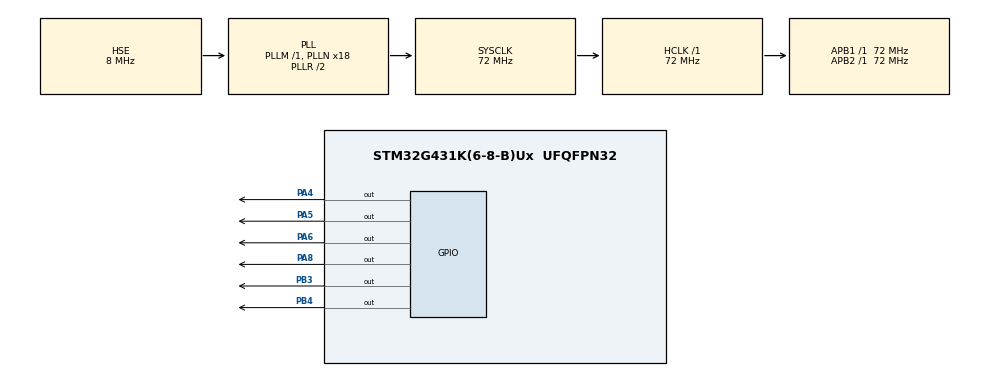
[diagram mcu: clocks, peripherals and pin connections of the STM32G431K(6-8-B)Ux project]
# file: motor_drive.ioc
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Mcu.Family=STM32G4
Mcu.Name=STM32G431K(6-8-B)Ux
Mcu.Package=UFQFPN32
NVIC.PriorityGroup=NVIC_PRIORITYGROUP_4
PA13.Mode=Serial_Wire
PA13.Signal=SYS_JTMS-SWDIO
PA14.Mode=Serial_Wire
PA14.Signal=SYS_JTCK-SWCLK
PA4.GPIO_PuPd=GPIO_PULLUP
PA4.PinState=GPIO_PIN_RESET
PA4.Signal=GPIO_Output
PA5.GPIO_PuPd=GPIO_PULLUP
PA5.PinState=GPIO_PIN_RESET
PA5.Signal=GPIO_Output
PA6.GPIO_PuPd=GPIO_PULLUP
PA6.PinState=GPIO_PIN_SET
PA6.Signal=GPIO_Output
PA8.GPIO_PuPd=GPIO_PULLUP
PA8.PinState=GPIO_PIN_SET
PA8.Signal=GPIO_Output
PB3.GPIO_PuPd=GPIO_PULLUP
PB3.GPIO_Speed=GPIO_SPEED_FREQ_VERY_HIGH
PB3.Signal=GPIO_Output
PB4.GPIO_PuPd=GPIO_PULLUP
PB4.GPIO_Speed=GPIO_SPEED_FREQ_VERY_HIGH
PB4.PinState=GPIO_PIN_SET
PB4.Signal=GPIO_Output
PF0-OSC_IN.Mode=HSE-External-Oscillator
PF0-OSC_IN.Signal=RCC_OSC_IN
PF1-OSC_OUT.Mode=HSE-External-Oscillator
PF1-OSC_OUT.Signal=RCC_OSC_OUT
ProjectManager.HeapSize=0x200
ProjectManager.StackSize=0x400
ProjectManager.TargetToolchain=MDK-ARM V5.32
RCC.ADC12Freq_Value=72000000
RCC.AHBFreq_Value=72000000
RCC.APB1Freq_Value=72000000
RCC.APB1TimFreq_Value=72000000
RCC.APB2Freq_Value=72000000
RCC.APB2TimFreq_Value=72000000
RCC.CortexFreq_Value=72000000
RCC.EXTERNAL_CLOCK_VALUE=12288000
RCC.HCLKFreq_Value=72000000
RCC.HSE_VALUE=8000000
RCC.HSI48_VALUE=48000000
RCC.HSI_VALUE=16000000
RCC.LSE_VALUE=32768
RCC.PLLN=18
RCC.PLLSourceVirtual=RCC_PLLSOURCE_HSE
RCC.SYSCLKFreq_VALUE=72000000
RCC.SYSCLKSource=RCC_SYSCLKSOURCE_PLLCLK
RCC.USBFreq_Value=72000000
RCC.VCOOutputFreq_Value=144000000
VP_SYS_VS_DBSignals.Mode=DisableDeadBatterySignals
board=custom

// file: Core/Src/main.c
/* USER CODE BEGIN Header */
/**
  ******************************************************************************
  * @file           : main.c
  * @brief          : Main program body
  ******************************************************************************
  * @attention
  *
  * Copyright (c) 2024 STMicroelectronics.
  * All rights reserved.
  *
  * This software is licensed under terms that can be found in the LICENSE file
  * in the root directory of this software component.
  * If no LICENSE file comes with this software, it is provided AS-IS.
  *
  ******************************************************************************
  */
/* USER CODE END Header */
#include "main.h"

void SystemClock_Config(void);
static void MX_GPIO_Init(void);

/* USER CODE BEGIN 0 */
	uint16_t a =11, b =1;
/* USER CODE END 0 */

int main(void)
{

  /* MCU Configuration--------------------------------------------------------*/

  /* Reset of all peripherals, Initializes the Flash interface and the Systick. */
  HAL_Init();

  /* Configure the system clock */
  SystemClock_Config();

  /* Initialize all configured peripherals */
  MX_GPIO_Init();

  /* Infinite loop */
  while (1)
  {
		HAL_GPIO_WritePin(GPIOA,GPIO_PIN_5,GPIO_PIN_RESET);
		for(uint8_t i = 0;i <= 60;i++) {
		HAL_GPIO_WritePin(GPIOA,GPIO_PIN_4,GPIO_PIN_SET);
		HAL_Delay(11);
		HAL_GPIO_WritePin(GPIOA,GPIO_PIN_4, GPIO_PIN_RESET);
		HAL_Delay(1);
		}

		HAL_GPIO_WritePin(GPIOA,GPIO_PIN_4,GPIO_PIN_SET);
		HAL_GPIO_WritePin(GPIOA,GPIO_PIN_5,GPIO_PIN_SET);
		HAL_Delay(750);
  }
}

void SystemClock_Config(void)
{
  RCC_OscInitTypeDef RCC_OscInitStruct = {0};
  RCC_ClkInitTypeDef RCC_ClkInitStruct = {0};

  /** Configure the main internal regulator output voltage
  */
  HAL_PWREx_ControlVoltageScaling(PWR_REGULATOR_VOLTAGE_SCALE1);

  /** Initializes the RCC Oscillators according to the specified parameters
  * in the RCC_OscInitTypeDef structure.
  */
  RCC_OscInitStruct.OscillatorType = RCC_OSCILLATORTYPE_HSE;
  RCC_OscInitStruct.HSEState = RCC_HSE_ON;
  RCC_OscInitStruct.PLL.PLLState = RCC_PLL_ON;
  RCC_OscInitStruct.PLL.PLLSource = RCC_PLLSOURCE_HSE;
  RCC_OscInitStruct.PLL.PLLM = RCC_PLLM_DIV1;
  RCC_OscInitStruct.PLL.PLLN = 18;
  RCC_OscInitStruct.PLL.PLLP = RCC_PLLP_DIV2;
  RCC_OscInitStruct.PLL.PLLQ = RCC_PLLQ_DIV2;
  RCC_OscInitStruct.PLL.PLLR = RCC_PLLR_DIV2;
  if (HAL_RCC_OscConfig(&RCC_OscInitStruct) != HAL_OK)
  {
    Error_Handler();
  }

  /** Initializes the CPU, AHB and APB buses clocks
  */
  RCC_ClkInitStruct.ClockType = RCC_CLOCKTYPE_HCLK|RCC_CLOCKTYPE_SYSCLK
                              |RCC_CLOCKTYPE_PCLK1|RCC_CLOCKTYPE_PCLK2;
  RCC_ClkInitStruct.SYSCLKSource = RCC_SYSCLKSOURCE_PLLCLK;
  RCC_ClkInitStruct.AHBCLKDivider = RCC_SYSCLK_DIV1;
  RCC_ClkInitStruct.APB1CLKDivider = RCC_HCLK_DIV1;
  RCC_ClkInitStruct.APB2CLKDivider = RCC_HCLK_DIV1;

  if (HAL_RCC_ClockConfig(&RCC_ClkInitStruct, FLASH_LATENCY_2) != HAL_OK)
  {
    Error_Handler();
  }
}

static void MX_GPIO_Init(void)
{
  GPIO_InitTypeDef GPIO_InitStruct = {0};

  /* GPIO Ports Clock Enable */
  __HAL_RCC_GPIOF_CLK_ENABLE();
  __HAL_RCC_GPIOA_CLK_ENABLE();
  __HAL_RCC_GPIOB_CLK_ENABLE();

  /*Configure GPIO pin Output Level */
  HAL_GPIO_WritePin(GPIOA, GPIO_PIN_4|GPIO_PIN_5, GPIO_PIN_RESET);

  /*Configure GPIO pin Output Level */
  HAL_GPIO_WritePin(GPIOA, GPIO_PIN_6|GPIO_PIN_8, GPIO_PIN_SET);

  /*Configure GPIO pin Output Level */
  HAL_GPIO_WritePin(GPIOB, GPIO_PIN_3, GPIO_PIN_RESET);

  /*Configure GPIO pin Output Level */
  HAL_GPIO_WritePin(GPIOB, GPIO_PIN_4, GPIO_PIN_SET);

  /*Configure GPIO pins : PA4 PA5 PA6 PA8 */
  GPIO_InitStruct.Pin = GPIO_PIN_4|GPIO_PIN_5|GPIO_PIN_6|GPIO_PIN_8;
  GPIO_InitStruct.Mode = GPIO_MODE_OUTPUT_PP;
  GPIO_InitStruct.Pull = GPIO_PULLUP;
  GPIO_InitStruct.Speed = GPIO_SPEED_FREQ_LOW;
  HAL_GPIO_Init(GPIOA, &GPIO_InitStruct);

  /*Configure GPIO pins : PB3 PB4 */
  GPIO_InitStruct.Pin = GPIO_PIN_3|GPIO_PIN_4;
  GPIO_InitStruct.Mode = GPIO_MODE_OUTPUT_PP;
  GPIO_InitStruct.Pull = GPIO_PULLUP;
  GPIO_InitStruct.Speed = GPIO_SPEED_FREQ_VERY_HIGH;
  HAL_GPIO_Init(GPIOB, &GPIO_InitStruct);

}

void Error_Handler(void)
{
  __disable_irq();
  while (1)
  {
  }
}
